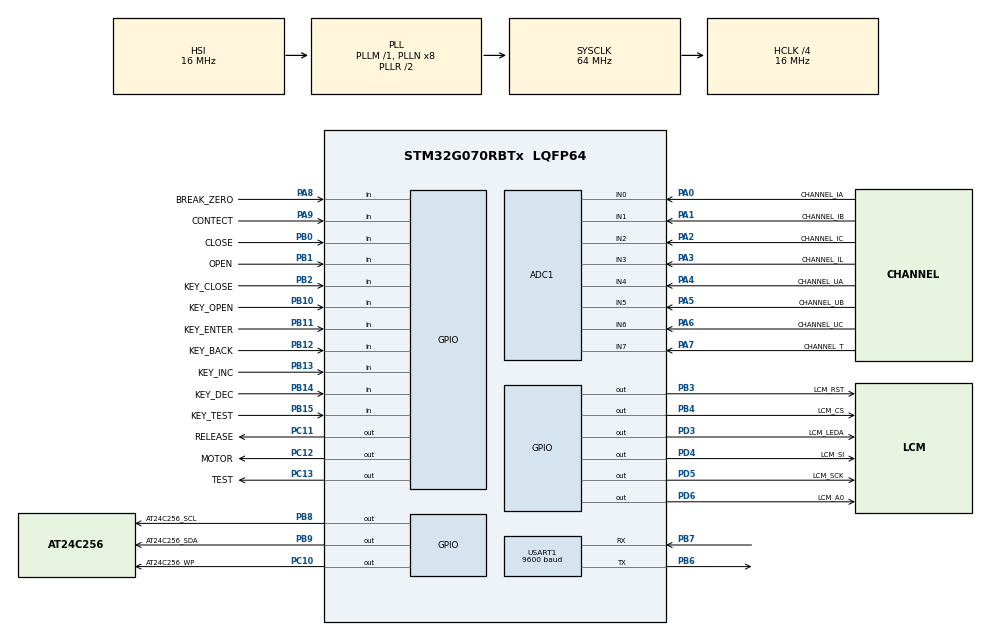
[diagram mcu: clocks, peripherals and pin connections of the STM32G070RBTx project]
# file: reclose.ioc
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ADC1.Channel-0\#ChannelRegularConversion=ADC_CHANNEL_0
ADC1.NbrOfConversionFlag=1
ADC1.Rank-0\#ChannelRegularConversion=1
ADC1.SamplingTime-0\#ChannelRegularConversion=ADC_SAMPLINGTIME_COMMON_1
ADC1.SamplingTimeCommon1=ADC_SAMPLETIME_39CYCLES_5
ADC1.SamplingTimeCommon2=ADC_SAMPLETIME_39CYCLES_5
ADC1.master=1
Mcu.Family=STM32G0
Mcu.Name=STM32G070RBTx
Mcu.Package=LQFP64
NVIC.TIM3_IRQn=true\:0\:0\:false\:false\:true\:true\:true
NVIC.USART1_IRQn=true\:0\:0\:false\:false\:true\:true\:true
PA0.GPIO_Label=CHANNEL_IA
PA0.Mode=IN0
PA0.Signal=ADC1_IN0
PA1.GPIO_Label=CHANNEL_IB
PA1.Mode=IN1
PA1.Signal=ADC1_IN1
PA13.Mode=Serial_Wire
PA13.Signal=SYS_SWDIO
PA14-BOOT0.Mode=Serial_Wire
PA14-BOOT0.Signal=SYS_SWCLK
PA2.GPIO_Label=CHANNEL_IC
PA2.Mode=IN2
PA2.Signal=ADC1_IN2
PA3.GPIO_Label=CHANNEL_IL
PA3.Mode=IN3
PA3.Signal=ADC1_IN3
PA4.GPIO_Label=CHANNEL_UA
PA4.Mode=IN4
PA4.Signal=ADC1_IN4
PA5.GPIO_Label=CHANNEL_UB
PA5.Mode=IN5
PA5.Signal=ADC1_IN5
PA6.GPIO_Label=CHANNEL_UC
PA6.Mode=IN6
PA6.Signal=ADC1_IN6
PA7.GPIO_Label=CHANNEL_T
PA7.Mode=IN7
PA7.Signal=ADC1_IN7
PA8.GPIO_Label=BREAK_ZERO
PA8.Signal=GPIO_Input
PA9.GPIO_Label=CONTECT
PA9.Signal=GPIO_Input
PB0.GPIO_Label=CLOSE
PB0.Signal=GPIO_Input
PB1.GPIO_Label=OPEN
PB1.Signal=GPIO_Input
PB10.GPIO_Label=KEY_OPEN
PB10.GPIO_PuPd=GPIO_PULLUP
PB10.Signal=GPIO_Input
PB11.GPIO_Label=KEY_ENTER
PB11.GPIO_PuPd=GPIO_PULLUP
PB11.Signal=GPIO_Input
PB12.GPIO_Label=KEY_BACK
PB12.GPIO_PuPd=GPIO_PULLUP
PB12.Signal=GPIO_Input
PB13.GPIO_Label=KEY_INC
PB13.GPIO_PuPd=GPIO_PULLUP
PB13.Signal=GPIO_Input
PB14.GPIO_Label=KEY_DEC
PB14.GPIO_PuPd=GPIO_PULLUP
PB14.Signal=GPIO_Input
PB15.GPIO_Label=KEY_TEST
PB15.GPIO_PuPd=GPIO_PULLUP
PB15.Signal=GPIO_Input
PB2.GPIO_Label=KEY_CLOSE
PB2.GPIO_PuPd=GPIO_PULLUP
PB2.Signal=GPIO_Input
PB3.GPIO_Label=LCM_RST
PB3.Signal=GPIO_Output
PB4.GPIO_Label=LCM_CS
PB4.Signal=GPIO_Output
PB6.Mode=Asynchronous
PB6.Signal=USART1_TX
PB7.Mode=Asynchronous
PB7.Signal=USART1_RX
PB8.GPIO_Label=AT24C256_SCL
PB8.Signal=GPIO_Output
PB9.GPIO_Label=AT24C256_SDA
PB9.Signal=GPIO_Output
PC10.GPIO_Label=AT24C256_WP
PC10.Signal=GPIO_Output
PC11.GPIO_Label=RELEASE
PC11.Signal=GPIO_Output
PC12.GPIO_Label=MOTOR
PC12.Signal=GPIO_Output
PC13.GPIO_Label=TEST
PC13.Signal=GPIO_Output
PC14-OSC32_IN\ (PC14).Mode=LSE-External-Oscillator
PC14-OSC32_IN\ (PC14).Signal=RCC_OSC32_IN
PC15-OSC32_OUT\ (PC15).Mode=LSE-External-Oscillator
PC15-OSC32_OUT\ (PC15).Signal=RCC_OSC32_OUT
PD3.GPIO_Label=LCM_LEDA
PD3.Signal=GPIO_Output
PD4.GPIO_Label=LCM_SI
PD4.Signal=GPIO_Output
PD5.GPIO_Label=LCM_SCK
PD5.Signal=GPIO_Output
PD6.GPIO_Label=LCM_A0
PD6.Signal=GPIO_Output
ProjectManager.HeapSize=0x200
ProjectManager.StackSize=0x400
ProjectManager.TargetToolchain=MDK-ARM V5
RCC.ADCFreq_Value=64000000
RCC.AHBCLKDivider=RCC_SYSCLK_DIV4
RCC.AHBFreq_Value=16000000
RCC.CortexFreq_Value=16000000
RCC.EXTERNAL_CLOCK_VALUE=48000
RCC.HCLKFreq_Value=16000000
RCC.HSE_VALUE=8000000
RCC.HSI_VALUE=16000000
RCC.RTCClockSelection=RCC_RTCCLKSOURCE_LSE
RCC.SYSCLKFreq_VALUE=64000000
RCC.SYSCLKSource=RCC_SYSCLKSOURCE_PLLCLK
RCC.VCOOutputFreq_Value=128000000
TIM3.Period=624
TIM3.Prescaler=15
USART1.BaudRate=9600
USART1.Parity=PARITY_EVEN
USART1.VirtualMode-Asynchronous=VM_ASYNC
USART1.WordLength=WORDLENGTH_8B
VP_IWDG_VS_IWDG.Mode=IWDG_Activate
VP_RTC_VS_RTC_Activate.Mode=RTC_Enabled
VP_RTC_VS_RTC_Calendar.Mode=RTC_Calendar
VP_TIM3_VS_ClockSourceINT.Mode=Internal
board=custom

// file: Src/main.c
/* USER CODE BEGIN Header */
/**
  ******************************************************************************
  * @file           : main.c
  * @brief          : Main program body
  ******************************************************************************
  * @attention
  *
  * <h2><center>&copy; Copyright (c) 2022 STMicroelectronics.
  * All rights reserved.</center></h2>
  *
  * This software component is licensed by ST under BSD 3-Clause license,
  * the "License"; You may not use this file except in compliance with the
  * License. You may obtain a copy of the License at:
  *                        opensource.org/licenses/BSD-3-Clause
  *
  ******************************************************************************
  */
/* USER CODE END Header */

#include "main.h"
#include "adc.h"
#include "iwdg.h"
#include "rtc.h"
#include "tim.h"
#include "usart.h"
#include "gpio.h"

void SystemClock_Config(void);

int main(void)
{

  /* MCU Configuration--------------------------------------------------------*/

  /* Reset of all peripherals, Initializes the Flash interface and the Systick. */
  HAL_Init();

  /* Configure the system clock */
  SystemClock_Config();

  /* Initialize all configured peripherals */
  MX_GPIO_Init();
  MX_ADC1_Init();
  MX_IWDG_Init();
  MX_RTC_Init();
  MX_TIM3_Init();
  MX_USART1_UART_Init();

  /* Infinite loop */
  /* USER CODE BEGIN WHILE */
  while (1)
  {
    HAL_Delay(500);
    HAL_GPIO_TogglePin(LCM_LEDA_GPIO_Port, LCM_LEDA_Pin);

    /* USER CODE END WHILE */

  }
}

void SystemClock_Config(void)
{
  RCC_OscInitTypeDef RCC_OscInitStruct = {0};
  RCC_ClkInitTypeDef RCC_ClkInitStruct = {0};
  RCC_PeriphCLKInitTypeDef PeriphClkInit = {0};

  /** Configure the main internal regulator output voltage
  */
  HAL_PWREx_ControlVoltageScaling(PWR_REGULATOR_VOLTAGE_SCALE1);
  /** Configure LSE Drive Capability
  */
  __HAL_RCC_LSEDRIVE_CONFIG(RCC_LSEDRIVE_LOW);
  /** Initializes the CPU, AHB and APB busses clocks
  */
  RCC_OscInitStruct.OscillatorType = RCC_OSCILLATORTYPE_HSI|RCC_OSCILLATORTYPE_LSI
                              |RCC_OSCILLATORTYPE_LSE;
  RCC_OscInitStruct.LSEState = RCC_LSE_ON;
  RCC_OscInitStruct.HSIState = RCC_HSI_ON;
  RCC_OscInitStruct.HSIDiv = RCC_HSI_DIV1;
  RCC_OscInitStruct.HSICalibrationValue = RCC_HSICALIBRATION_DEFAULT;
  RCC_OscInitStruct.LSIState = RCC_LSI_ON;
  RCC_OscInitStruct.PLL.PLLState = RCC_PLL_ON;
  RCC_OscInitStruct.PLL.PLLSource = RCC_PLLSOURCE_HSI;
  RCC_OscInitStruct.PLL.PLLM = RCC_PLLM_DIV1;
  RCC_OscInitStruct.PLL.PLLN = 8;
  RCC_OscInitStruct.PLL.PLLP = RCC_PLLP_DIV2;
  RCC_OscInitStruct.PLL.PLLR = RCC_PLLR_DIV2;
  if (HAL_RCC_OscConfig(&RCC_OscInitStruct) != HAL_OK)
  {
    Error_Handler();
  }
  /** Initializes the CPU, AHB and APB busses clocks
  */
  RCC_ClkInitStruct.ClockType = RCC_CLOCKTYPE_HCLK|RCC_CLOCKTYPE_SYSCLK
                              |RCC_CLOCKTYPE_PCLK1;
  RCC_ClkInitStruct.SYSCLKSource = RCC_SYSCLKSOURCE_PLLCLK;
  RCC_ClkInitStruct.AHBCLKDivider = RCC_SYSCLK_DIV4;
  RCC_ClkInitStruct.APB1CLKDivider = RCC_HCLK_DIV1;

  if (HAL_RCC_ClockConfig(&RCC_ClkInitStruct, FLASH_LATENCY_0) != HAL_OK)
  {
    Error_Handler();
  }
  /** Initializes the peripherals clocks
  */
  PeriphClkInit.PeriphClockSelection = RCC_PERIPHCLK_RTC|RCC_PERIPHCLK_USART1
                              |RCC_PERIPHCLK_ADC;
  PeriphClkInit.Usart1ClockSelection = RCC_USART1CLKSOURCE_PCLK1;
  PeriphClkInit.AdcClockSelection = RCC_ADCCLKSOURCE_SYSCLK;
  PeriphClkInit.RTCClockSelection = RCC_RTCCLKSOURCE_LSE;

  if (HAL_RCCEx_PeriphCLKConfig(&PeriphClkInit) != HAL_OK)
  {
    Error_Handler();
  }
}

void Error_Handler(void)
{
}

/************************ (C) COPYRIGHT STMicroelectronics *****END OF FILE****/
